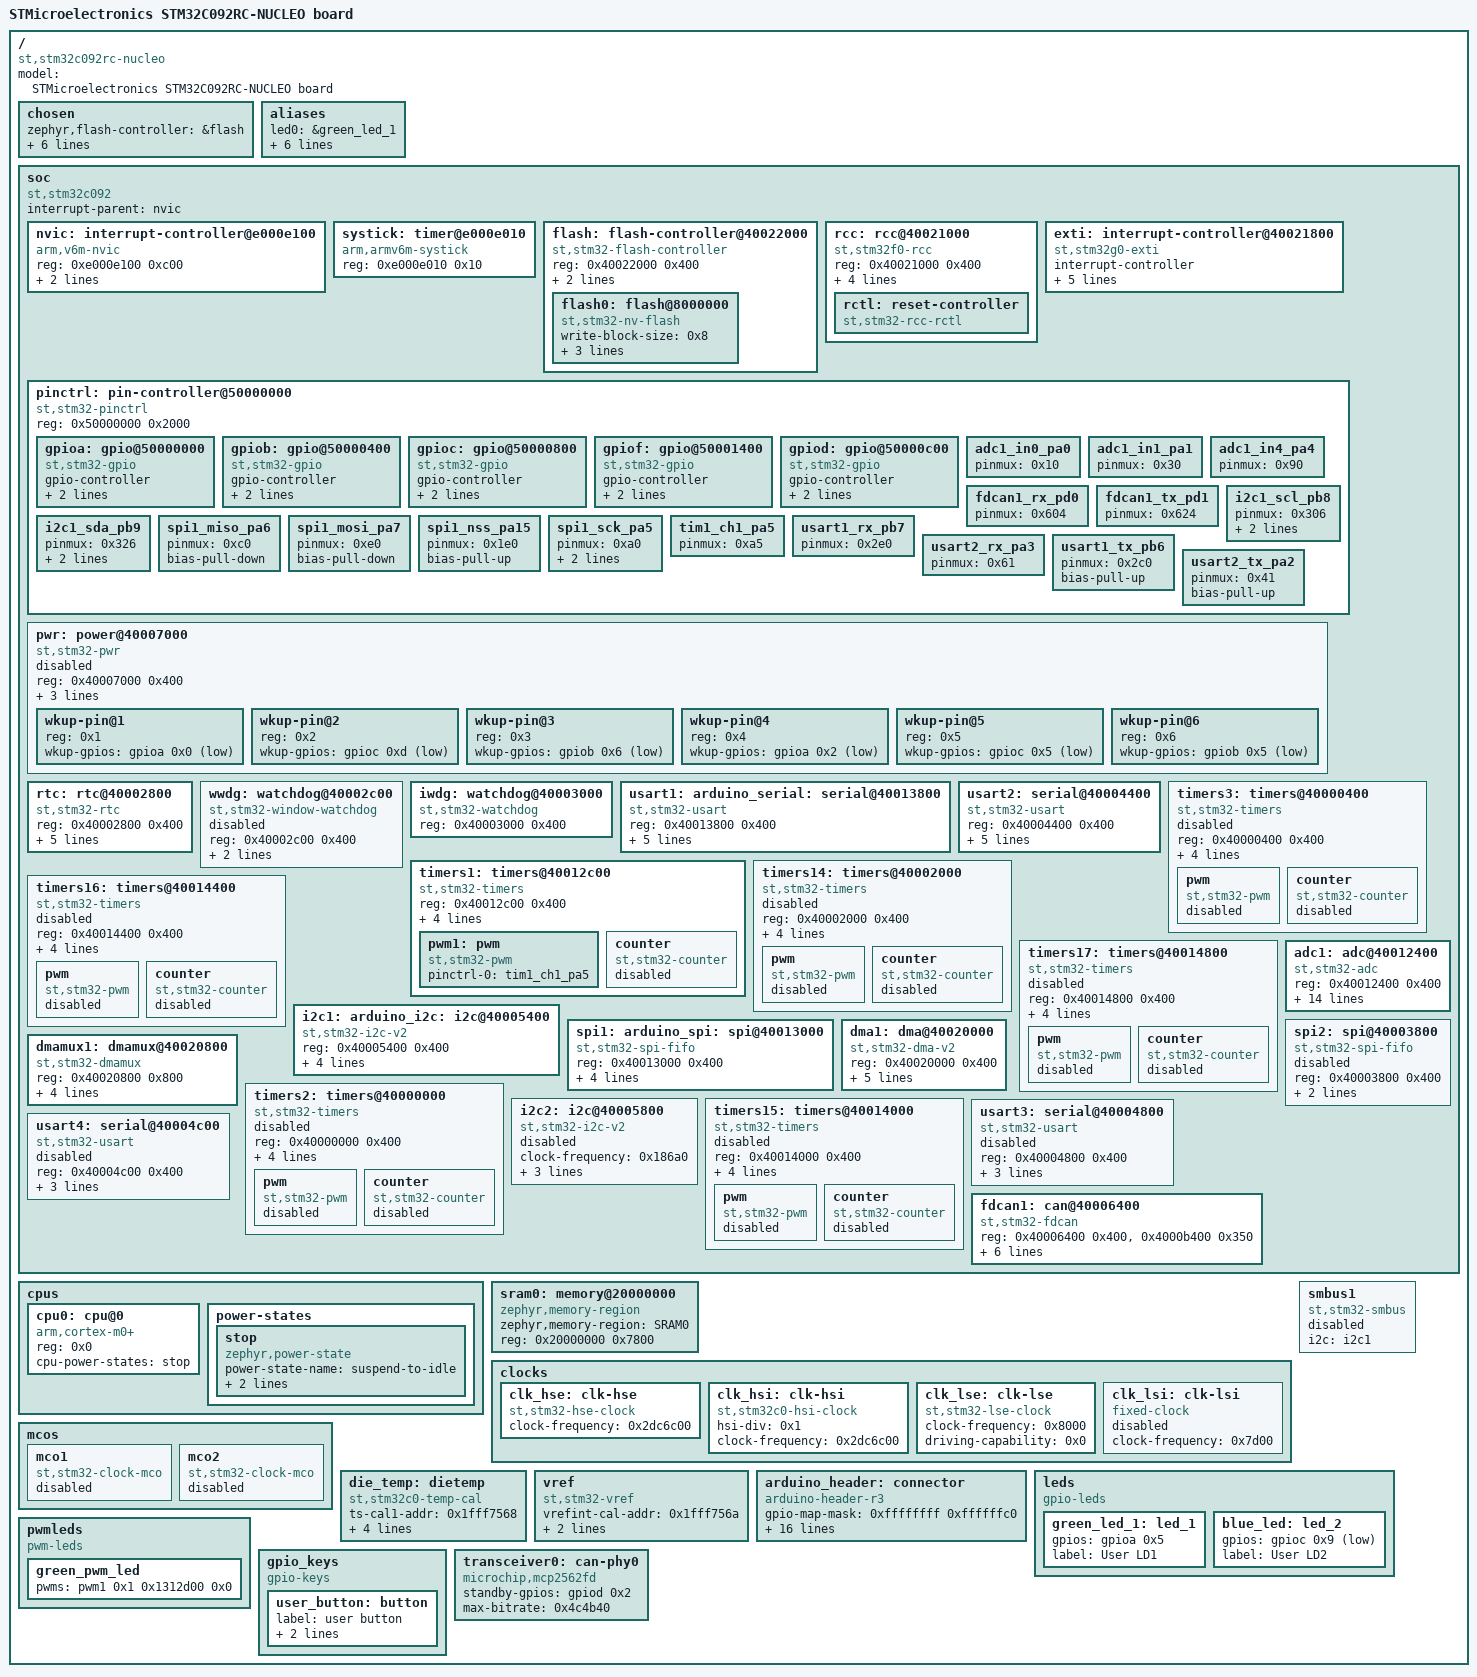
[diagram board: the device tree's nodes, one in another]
/dts-v1/;

/* node '/' defined in zephyr/dts/common/skeleton.dtsi:9 */
/ {
	#address-cells = < 0x1 >;                              /* in zephyr/dts/common/skeleton.dtsi:10 */
	#size-cells = < 0x1 >;                                 /* in zephyr/dts/common/skeleton.dtsi:11 */
	model = "STMicroelectronics STM32C092RC-NUCLEO board"; /* in zephyr/boards/st/nucleo_c092rc/nucleo_c092rc.dts:15 */
	compatible = "st,stm32c092rc-nucleo";                  /* in zephyr/boards/st/nucleo_c092rc/nucleo_c092rc.dts:16 */

	/* node '/chosen' defined in zephyr/dts/common/skeleton.dtsi:13 */
	chosen {
		zephyr,flash-controller = &flash;  /* in zephyr/dts/arm/st/c0/stm32c0.dtsi:75 */
		zephyr,cortex-m-idle-timer = &rtc; /* in zephyr/dts/arm/st/c0/stm32c0.dtsi:76 */
		zephyr,console = &usart2;          /* in zephyr/boards/st/nucleo_c092rc/nucleo_c092rc.dts:19 */
		zephyr,shell-uart = &usart2;       /* in zephyr/boards/st/nucleo_c092rc/nucleo_c092rc.dts:20 */
		zephyr,sram = &sram0;              /* in zephyr/boards/st/nucleo_c092rc/nucleo_c092rc.dts:21 */
		zephyr,flash = &flash0;            /* in zephyr/boards/st/nucleo_c092rc/nucleo_c092rc.dts:22 */
		zephyr,canbus = &fdcan1;           /* in zephyr/boards/st/nucleo_c092rc/nucleo_c092rc.dts:23 */
	};

	/* node '/aliases' defined in zephyr/dts/common/skeleton.dtsi:15 */
	aliases {
		led0 = &green_led_1;       /* in zephyr/boards/st/nucleo_c092rc/nucleo_c092rc.dts:67 */
		led1 = &blue_led;          /* in zephyr/boards/st/nucleo_c092rc/nucleo_c092rc.dts:68 */
		pwm-led0 = &green_pwm_led; /* in zephyr/boards/st/nucleo_c092rc/nucleo_c092rc.dts:69 */
		sw0 = &user_button;        /* in zephyr/boards/st/nucleo_c092rc/nucleo_c092rc.dts:70 */
		watchdog0 = &iwdg;         /* in zephyr/boards/st/nucleo_c092rc/nucleo_c092rc.dts:71 */
		die-temp0 = &die_temp;     /* in zephyr/boards/st/nucleo_c092rc/nucleo_c092rc.dts:72 */
		volt-sensor0 = &vref;      /* in zephyr/boards/st/nucleo_c092rc/nucleo_c092rc.dts:73 */
	};

	/* node '/soc' defined in zephyr/dts/arm/armv6-m.dtsi:6 */
	soc {
		#address-cells = < 0x1 >;     /* in zephyr/dts/arm/armv6-m.dtsi:7 */
		#size-cells = < 0x1 >;        /* in zephyr/dts/arm/armv6-m.dtsi:8 */
		interrupt-parent = < &nvic >; /* in zephyr/dts/arm/armv6-m.dtsi:10 */
		ranges;                       /* in zephyr/dts/arm/armv6-m.dtsi:11 */
		compatible = "st,stm32c092",
		             "st,stm32c0",
		             "simple-bus";    /* in zephyr/dts/arm/st/c0/stm32c092.dtsi:11 */

		/* node '/soc/interrupt-controller@e000e100' defined in zephyr/dts/arm/armv6-m.dtsi:13 */
		nvic: interrupt-controller@e000e100 {
			#address-cells = < 0x1 >;            /* in zephyr/dts/arm/armv6-m.dtsi:14 */
			compatible = "arm,v6m-nvic";         /* in zephyr/dts/arm/armv6-m.dtsi:15 */
			reg = < 0xe000e100 0xc00 >;          /* in zephyr/dts/arm/armv6-m.dtsi:16 */
			interrupt-controller;                /* in zephyr/dts/arm/armv6-m.dtsi:17 */
			#interrupt-cells = < 0x2 >;          /* in zephyr/dts/arm/armv6-m.dtsi:18 */
			arm,num-irq-priority-bits = < 0x2 >; /* in zephyr/dts/arm/st/c0/stm32c0.dtsi:526 */
			phandle = < 0x1 >;                   /* in zephyr/dts/arm/armv6-m.dtsi:10 */
		};

		/* node '/soc/timer@e000e010' defined in zephyr/dts/arm/armv6-m.dtsi:21 */
		systick: timer@e000e010 {
			compatible = "arm,armv6m-systick"; /* in zephyr/dts/arm/armv6-m.dtsi:22 */
			reg = < 0xe000e010 0x10 >;         /* in zephyr/dts/arm/armv6-m.dtsi:23 */
		};

		/* node '/soc/flash-controller@40022000' defined in zephyr/dts/arm/st/c0/stm32c0.dtsi:155 */
		flash: flash-controller@40022000 {
			compatible = "st,stm32-flash-controller",
			             "st,stm32g0-flash-controller"; /* in zephyr/dts/arm/st/c0/stm32c0.dtsi:156 */
			reg = < 0x40022000 0x400 >;                 /* in zephyr/dts/arm/st/c0/stm32c0.dtsi:157 */
			interrupts = < 0x3 0x0 >;                   /* in zephyr/dts/arm/st/c0/stm32c0.dtsi:158 */
			clocks = < &rcc 0x38 0x100 >;               /* in zephyr/dts/arm/st/c0/stm32c0.dtsi:159 */
			#address-cells = < 0x1 >;                   /* in zephyr/dts/arm/st/c0/stm32c0.dtsi:161 */
			#size-cells = < 0x1 >;                      /* in zephyr/dts/arm/st/c0/stm32c0.dtsi:162 */

			/* node '/soc/flash-controller@40022000/flash@8000000' defined in zephyr/dts/arm/st/c0/stm32c0.dtsi:164 */
			flash0: flash@8000000 {
				compatible = "st,stm32-nv-flash",
				             "soc-nv-flash";      /* in zephyr/dts/arm/st/c0/stm32c0.dtsi:165 */
				write-block-size = < 0x8 >;       /* in zephyr/dts/arm/st/c0/stm32c0.dtsi:167 */
				erase-block-size = < 0x800 >;     /* in zephyr/dts/arm/st/c0/stm32c0.dtsi:168 */
				max-erase-time = < 0x28 >;        /* in zephyr/dts/arm/st/c0/stm32c0.dtsi:170 */
				reg = < 0x8000000 0x40000 >;      /* in zephyr/dts/arm/st/c0/stm32c092Xc.dtsi:19 */
			};
		};

		/* node '/soc/rcc@40021000' defined in zephyr/dts/arm/st/c0/stm32c0.dtsi:174 */
		rcc: rcc@40021000 {
			compatible = "st,stm32f0-rcc";   /* in zephyr/dts/arm/st/c0/stm32c0.dtsi:175 */
			#clock-cells = < 0x2 >;          /* in zephyr/dts/arm/st/c0/stm32c0.dtsi:176 */
			reg = < 0x40021000 0x400 >;      /* in zephyr/dts/arm/st/c0/stm32c0.dtsi:177 */
			clocks = < &clk_hse >;           /* in zephyr/boards/st/nucleo_c092rc/nucleo_c092rc.dts:108 */
			clock-frequency = < 0x2dc6c00 >; /* in zephyr/boards/st/nucleo_c092rc/nucleo_c092rc.dts:109 */
			ahb-prescaler = < 0x1 >;         /* in zephyr/boards/st/nucleo_c092rc/nucleo_c092rc.dts:110 */
			apb1-prescaler = < 0x1 >;        /* in zephyr/boards/st/nucleo_c092rc/nucleo_c092rc.dts:111 */
			phandle = < 0x2 >;               /* in zephyr/dts/arm/st/c0/stm32c0.dtsi:159 */

			/* node '/soc/rcc@40021000/reset-controller' defined in zephyr/dts/arm/st/c0/stm32c0.dtsi:179 */
			rctl: reset-controller {
				compatible = "st,stm32-rcc-rctl"; /* in zephyr/dts/arm/st/c0/stm32c0.dtsi:180 */
				#reset-cells = < 0x1 >;           /* in zephyr/dts/arm/st/c0/stm32c0.dtsi:181 */
				phandle = < 0x7 >;                /* in zephyr/dts/arm/st/c0/stm32c0.dtsi:306 */
			};
		};

		/* node '/soc/interrupt-controller@40021800' defined in zephyr/dts/arm/st/c0/stm32c0.dtsi:185 */
		exti: interrupt-controller@40021800 {
			compatible = "st,stm32g0-exti",
			             "st,stm32-exti";   /* in zephyr/dts/arm/st/c0/stm32c0.dtsi:186 */
			interrupt-controller;           /* in zephyr/dts/arm/st/c0/stm32c0.dtsi:187 */
			#interrupt-cells = < 0x1 >;     /* in zephyr/dts/arm/st/c0/stm32c0.dtsi:188 */
			#address-cells = < 0x1 >;       /* in zephyr/dts/arm/st/c0/stm32c0.dtsi:189 */
			reg = < 0x40021800 0x400 >;     /* in zephyr/dts/arm/st/c0/stm32c0.dtsi:190 */
			clocks = < &rcc 0x40 0x1 >;     /* in zephyr/dts/arm/st/c0/stm32c0.dtsi:191 */
			num-lines = < 0x20 >;           /* in zephyr/dts/arm/st/c0/stm32c0.dtsi:192 */
			interrupts = < 0x5 0x0 >,
			             < 0x6 0x0 >,
			             < 0x7 0x0 >;       /* in zephyr/dts/arm/st/c0/stm32c0.dtsi:193 */
			interrupt-names = "line0-1",
			                  "line2-3",
			                  "line4-15";   /* in zephyr/dts/arm/st/c0/stm32c0.dtsi:194 */
			line-ranges = < 0x0 0x2 >,
			              < 0x2 0x2 >,
			              < 0x4 0xc >;      /* in zephyr/dts/arm/st/c0/stm32c0.dtsi:195 */
		};

		/* node '/soc/pin-controller@50000000' defined in zephyr/dts/arm/st/c0/stm32c0.dtsi:198 */
		pinctrl: pin-controller@50000000 {
			compatible = "st,stm32-pinctrl"; /* in zephyr/dts/arm/st/c0/stm32c0.dtsi:199 */
			#address-cells = < 0x1 >;        /* in zephyr/dts/arm/st/c0/stm32c0.dtsi:200 */
			#size-cells = < 0x1 >;           /* in zephyr/dts/arm/st/c0/stm32c0.dtsi:201 */
			reg = < 0x50000000 0x2000 >;     /* in zephyr/dts/arm/st/c0/stm32c0.dtsi:202 */

			/* node '/soc/pin-controller@50000000/gpio@50000000' defined in zephyr/dts/arm/st/c0/stm32c0.dtsi:204 */
			gpioa: gpio@50000000 {
				compatible = "st,stm32-gpio"; /* in zephyr/dts/arm/st/c0/stm32c0.dtsi:205 */
				gpio-controller;              /* in zephyr/dts/arm/st/c0/stm32c0.dtsi:206 */
				#gpio-cells = < 0x2 >;        /* in zephyr/dts/arm/st/c0/stm32c0.dtsi:207 */
				reg = < 0x50000000 0x400 >;   /* in zephyr/dts/arm/st/c0/stm32c0.dtsi:208 */
				clocks = < &rcc 0x34 0x1 >;   /* in zephyr/dts/arm/st/c0/stm32c0.dtsi:209 */
				phandle = < 0x4 >;            /* in zephyr/dts/arm/st/c0/stm32c0.dtsi:251 */
			};

			/* node '/soc/pin-controller@50000000/gpio@50000400' defined in zephyr/dts/arm/st/c0/stm32c0.dtsi:212 */
			gpiob: gpio@50000400 {
				compatible = "st,stm32-gpio"; /* in zephyr/dts/arm/st/c0/stm32c0.dtsi:213 */
				gpio-controller;              /* in zephyr/dts/arm/st/c0/stm32c0.dtsi:214 */
				#gpio-cells = < 0x2 >;        /* in zephyr/dts/arm/st/c0/stm32c0.dtsi:215 */
				reg = < 0x50000400 0x400 >;   /* in zephyr/dts/arm/st/c0/stm32c0.dtsi:216 */
				clocks = < &rcc 0x34 0x2 >;   /* in zephyr/dts/arm/st/c0/stm32c0.dtsi:217 */
				phandle = < 0x6 >;            /* in zephyr/dts/arm/st/c0/stm32c0.dtsi:260 */
			};

			/* node '/soc/pin-controller@50000000/gpio@50000800' defined in zephyr/dts/arm/st/c0/stm32c0.dtsi:220 */
			gpioc: gpio@50000800 {
				compatible = "st,stm32-gpio"; /* in zephyr/dts/arm/st/c0/stm32c0.dtsi:221 */
				gpio-controller;              /* in zephyr/dts/arm/st/c0/stm32c0.dtsi:222 */
				#gpio-cells = < 0x2 >;        /* in zephyr/dts/arm/st/c0/stm32c0.dtsi:223 */
				reg = < 0x50000800 0x400 >;   /* in zephyr/dts/arm/st/c0/stm32c0.dtsi:224 */
				clocks = < &rcc 0x34 0x4 >;   /* in zephyr/dts/arm/st/c0/stm32c0.dtsi:225 */
				phandle = < 0x5 >;            /* in zephyr/boards/st/nucleo_c092rc/nucleo_c092rc.dts:80 */
			};

			/* node '/soc/pin-controller@50000000/gpio@50001400' defined in zephyr/dts/arm/st/c0/stm32c0.dtsi:228 */
			gpiof: gpio@50001400 {
				compatible = "st,stm32-gpio"; /* in zephyr/dts/arm/st/c0/stm32c0.dtsi:229 */
				gpio-controller;              /* in zephyr/dts/arm/st/c0/stm32c0.dtsi:230 */
				#gpio-cells = < 0x2 >;        /* in zephyr/dts/arm/st/c0/stm32c0.dtsi:231 */
				reg = < 0x50001400 0x400 >;   /* in zephyr/dts/arm/st/c0/stm32c0.dtsi:232 */
				clocks = < &rcc 0x34 0x20 >;  /* in zephyr/dts/arm/st/c0/stm32c0.dtsi:233 */
			};

			/* node '/soc/pin-controller@50000000/gpio@50000c00' defined in zephyr/dts/arm/st/c0/stm32c031.dtsi:14 */
			gpiod: gpio@50000c00 {
				compatible = "st,stm32-gpio"; /* in zephyr/dts/arm/st/c0/stm32c031.dtsi:15 */
				gpio-controller;              /* in zephyr/dts/arm/st/c0/stm32c031.dtsi:16 */
				#gpio-cells = < 0x2 >;        /* in zephyr/dts/arm/st/c0/stm32c031.dtsi:17 */
				reg = < 0x50000c00 0x400 >;   /* in zephyr/dts/arm/st/c0/stm32c031.dtsi:18 */
				clocks = < &rcc 0x34 0x8 >;   /* in zephyr/dts/arm/st/c0/stm32c031.dtsi:19 */
				phandle = < 0x1d >;           /* in zephyr/boards/st/nucleo_c092rc/nucleo_c092rc.dts:61 */
			};

			/* node '/soc/pin-controller@50000000/adc1_in0_pa0' defined in modules/hal/stm32/dts/st/c0/stm32c092rctx-pinctrl.dtsi:15 */
			adc1_in0_pa0: adc1_in0_pa0 {
				pinmux = < 0x10 >;  /* in modules/hal/stm32/dts/st/c0/stm32c092rctx-pinctrl.dtsi:16 */
				phandle = < 0x13 >; /* in zephyr/boards/st/nucleo_c092rc/nucleo_c092rc.dts:165 */
			};

			/* node '/soc/pin-controller@50000000/adc1_in1_pa1' defined in modules/hal/stm32/dts/st/c0/stm32c092rctx-pinctrl.dtsi:19 */
			adc1_in1_pa1: adc1_in1_pa1 {
				pinmux = < 0x30 >;  /* in modules/hal/stm32/dts/st/c0/stm32c092rctx-pinctrl.dtsi:20 */
				phandle = < 0x14 >; /* in zephyr/boards/st/nucleo_c092rc/nucleo_c092rc.dts:165 */
			};

			/* node '/soc/pin-controller@50000000/adc1_in4_pa4' defined in modules/hal/stm32/dts/st/c0/stm32c092rctx-pinctrl.dtsi:31 */
			adc1_in4_pa4: adc1_in4_pa4 {
				pinmux = < 0x90 >;  /* in modules/hal/stm32/dts/st/c0/stm32c092rctx-pinctrl.dtsi:32 */
				phandle = < 0x15 >; /* in zephyr/boards/st/nucleo_c092rc/nucleo_c092rc.dts:165 */
			};

			/* node '/soc/pin-controller@50000000/fdcan1_rx_pd0' defined in modules/hal/stm32/dts/st/c0/stm32c092rctx-pinctrl.dtsi:367 */
			fdcan1_rx_pd0: fdcan1_rx_pd0 {
				pinmux = < 0x604 >; /* in modules/hal/stm32/dts/st/c0/stm32c092rctx-pinctrl.dtsi:368 */
				phandle = < 0x16 >; /* in zephyr/boards/st/nucleo_c092rc/nucleo_c092rc.dts:197 */
			};

			/* node '/soc/pin-controller@50000000/fdcan1_tx_pd1' defined in modules/hal/stm32/dts/st/c0/stm32c092rctx-pinctrl.dtsi:405 */
			fdcan1_tx_pd1: fdcan1_tx_pd1 {
				pinmux = < 0x624 >; /* in modules/hal/stm32/dts/st/c0/stm32c092rctx-pinctrl.dtsi:406 */
				phandle = < 0x17 >; /* in zephyr/boards/st/nucleo_c092rc/nucleo_c092rc.dts:197 */
			};

			/* node '/soc/pin-controller@50000000/i2c1_scl_pb8' defined in modules/hal/stm32/dts/st/c0/stm32c092rctx-pinctrl.dtsi:429 */
			i2c1_scl_pb8: i2c1_scl_pb8 {
				pinmux = < 0x306 >; /* in modules/hal/stm32/dts/st/c0/stm32c092rctx-pinctrl.dtsi:430 */
				bias-pull-up;       /* in modules/hal/stm32/dts/st/c0/stm32c092rctx-pinctrl.dtsi:431 */
				drive-open-drain;   /* in modules/hal/stm32/dts/st/c0/stm32c092rctx-pinctrl.dtsi:432 */
				phandle = < 0xd >;  /* in zephyr/boards/st/nucleo_c092rc/nucleo_c092rc.dts:150 */
			};

			/* node '/soc/pin-controller@50000000/i2c1_sda_pb9' defined in modules/hal/stm32/dts/st/c0/stm32c092rctx-pinctrl.dtsi:485 */
			i2c1_sda_pb9: i2c1_sda_pb9 {
				pinmux = < 0x326 >; /* in modules/hal/stm32/dts/st/c0/stm32c092rctx-pinctrl.dtsi:486 */
				bias-pull-up;       /* in modules/hal/stm32/dts/st/c0/stm32c092rctx-pinctrl.dtsi:487 */
				drive-open-drain;   /* in modules/hal/stm32/dts/st/c0/stm32c092rctx-pinctrl.dtsi:488 */
				phandle = < 0xe >;  /* in zephyr/boards/st/nucleo_c092rc/nucleo_c092rc.dts:150 */
			};

			/* node '/soc/pin-controller@50000000/spi1_miso_pa6' defined in modules/hal/stm32/dts/st/c0/stm32c092rctx-pinctrl.dtsi:710 */
			spi1_miso_pa6: spi1_miso_pa6 {
				pinmux = < 0xc0 >;  /* in modules/hal/stm32/dts/st/c0/stm32c092rctx-pinctrl.dtsi:711 */
				bias-pull-down;     /* in modules/hal/stm32/dts/st/c0/stm32c092rctx-pinctrl.dtsi:712 */
				phandle = < 0x11 >; /* in zephyr/boards/st/nucleo_c092rc/nucleo_c092rc.dts:158 */
			};

			/* node '/soc/pin-controller@50000000/spi1_mosi_pa7' defined in modules/hal/stm32/dts/st/c0/stm32c092rctx-pinctrl.dtsi:782 */
			spi1_mosi_pa7: spi1_mosi_pa7 {
				pinmux = < 0xe0 >;  /* in modules/hal/stm32/dts/st/c0/stm32c092rctx-pinctrl.dtsi:783 */
				bias-pull-down;     /* in modules/hal/stm32/dts/st/c0/stm32c092rctx-pinctrl.dtsi:784 */
				phandle = < 0x12 >; /* in zephyr/boards/st/nucleo_c092rc/nucleo_c092rc.dts:158 */
			};

			/* node '/soc/pin-controller@50000000/spi1_nss_pa15' defined in modules/hal/stm32/dts/st/c0/stm32c092rctx-pinctrl.dtsi:859 */
			spi1_nss_pa15: spi1_nss_pa15 {
				pinmux = < 0x1e0 >; /* in modules/hal/stm32/dts/st/c0/stm32c092rctx-pinctrl.dtsi:860 */
				bias-pull-up;       /* in modules/hal/stm32/dts/st/c0/stm32c092rctx-pinctrl.dtsi:861 */
				phandle = < 0xf >;  /* in zephyr/boards/st/nucleo_c092rc/nucleo_c092rc.dts:158 */
			};

			/* node '/soc/pin-controller@50000000/spi1_sck_pa5' defined in modules/hal/stm32/dts/st/c0/stm32c092rctx-pinctrl.dtsi:907 */
			spi1_sck_pa5: spi1_sck_pa5 {
				pinmux = < 0xa0 >;             /* in modules/hal/stm32/dts/st/c0/stm32c092rctx-pinctrl.dtsi:908 */
				bias-pull-down;                /* in modules/hal/stm32/dts/st/c0/stm32c092rctx-pinctrl.dtsi:909 */
				slew-rate = "very-high-speed"; /* in modules/hal/stm32/dts/st/c0/stm32c092rctx-pinctrl.dtsi:910 */
				phandle = < 0x10 >;            /* in zephyr/boards/st/nucleo_c092rc/nucleo_c092rc.dts:158 */
			};

			/* node '/soc/pin-controller@50000000/tim1_ch1_pa5' defined in modules/hal/stm32/dts/st/c0/stm32c092rctx-pinctrl.dtsi:1053 */
			tim1_ch1_pa5: tim1_ch1_pa5 {
				pinmux = < 0xa5 >; /* in modules/hal/stm32/dts/st/c0/stm32c092rctx-pinctrl.dtsi:1054 */
				phandle = < 0xc >; /* in zephyr/boards/st/nucleo_c092rc/nucleo_c092rc.dts:143 */
			};

			/* node '/soc/pin-controller@50000000/usart1_rx_pb7' defined in modules/hal/stm32/dts/st/c0/stm32c092rctx-pinctrl.dtsi:1637 */
			usart1_rx_pb7: usart1_rx_pb7 {
				pinmux = < 0x2e0 >; /* in modules/hal/stm32/dts/st/c0/stm32c092rctx-pinctrl.dtsi:1638 */
				phandle = < 0x9 >;  /* in zephyr/boards/st/nucleo_c092rc/nucleo_c092rc.dts:115 */
			};

			/* node '/soc/pin-controller@50000000/usart2_rx_pa3' defined in modules/hal/stm32/dts/st/c0/stm32c092rctx-pinctrl.dtsi:1645 */
			usart2_rx_pa3: usart2_rx_pa3 {
				pinmux = < 0x61 >; /* in modules/hal/stm32/dts/st/c0/stm32c092rctx-pinctrl.dtsi:1646 */
				phandle = < 0xb >; /* in zephyr/boards/st/nucleo_c092rc/nucleo_c092rc.dts:122 */
			};

			/* node '/soc/pin-controller@50000000/usart1_tx_pb6' defined in modules/hal/stm32/dts/st/c0/stm32c092rctx-pinctrl.dtsi:1721 */
			usart1_tx_pb6: usart1_tx_pb6 {
				pinmux = < 0x2c0 >; /* in modules/hal/stm32/dts/st/c0/stm32c092rctx-pinctrl.dtsi:1722 */
				bias-pull-up;       /* in modules/hal/stm32/dts/st/c0/stm32c092rctx-pinctrl.dtsi:1723 */
				phandle = < 0x8 >;  /* in zephyr/boards/st/nucleo_c092rc/nucleo_c092rc.dts:115 */
			};

			/* node '/soc/pin-controller@50000000/usart2_tx_pa2' defined in modules/hal/stm32/dts/st/c0/stm32c092rctx-pinctrl.dtsi:1736 */
			usart2_tx_pa2: usart2_tx_pa2 {
				pinmux = < 0x41 >; /* in modules/hal/stm32/dts/st/c0/stm32c092rctx-pinctrl.dtsi:1737 */
				bias-pull-up;      /* in modules/hal/stm32/dts/st/c0/stm32c092rctx-pinctrl.dtsi:1738 */
				phandle = < 0xa >; /* in zephyr/boards/st/nucleo_c092rc/nucleo_c092rc.dts:122 */
			};
		};

		/* node '/soc/power@40007000' defined in zephyr/dts/arm/st/c0/stm32c0.dtsi:237 */
		pwr: power@40007000 {
			compatible = "st,stm32-pwr"; /* in zephyr/dts/arm/st/c0/stm32c0.dtsi:238 */
			reg = < 0x40007000 0x400 >;  /* in zephyr/dts/arm/st/c0/stm32c0.dtsi:239 */
			status = "disabled";         /* in zephyr/dts/arm/st/c0/stm32c0.dtsi:240 */
			wkup-pins-nb = < 0x6 >;      /* in zephyr/dts/arm/st/c0/stm32c0.dtsi:242 */
			wkup-pins-pol;               /* in zephyr/dts/arm/st/c0/stm32c0.dtsi:243 */
			wkup-pins-pupd;              /* in zephyr/dts/arm/st/c0/stm32c0.dtsi:244 */
			#address-cells = < 0x1 >;    /* in zephyr/dts/arm/st/c0/stm32c0.dtsi:246 */
			#size-cells = < 0x0 >;       /* in zephyr/dts/arm/st/c0/stm32c0.dtsi:247 */

			/* node '/soc/power@40007000/wkup-pin@1' defined in zephyr/dts/arm/st/c0/stm32c0.dtsi:249 */
			wkup-pin@1 {
				reg = < 0x1 >;                   /* in zephyr/dts/arm/st/c0/stm32c0.dtsi:250 */
				wkup-gpios = < &gpioa 0x0 0x1 >; /* in zephyr/dts/arm/st/c0/stm32c0.dtsi:251 */
			};

			/* node '/soc/power@40007000/wkup-pin@2' defined in zephyr/dts/arm/st/c0/stm32c0.dtsi:254 */
			wkup-pin@2 {
				reg = < 0x2 >;                   /* in zephyr/boards/st/nucleo_c092rc/nucleo_c092rc.dts:79 */
				wkup-gpios = < &gpioc 0xd 0x1 >; /* in zephyr/boards/st/nucleo_c092rc/nucleo_c092rc.dts:80 */
			};

			/* node '/soc/power@40007000/wkup-pin@3' defined in zephyr/dts/arm/st/c0/stm32c0.dtsi:258 */
			wkup-pin@3 {
				reg = < 0x3 >;                   /* in zephyr/dts/arm/st/c0/stm32c0.dtsi:259 */
				wkup-gpios = < &gpiob 0x6 0x1 >; /* in zephyr/dts/arm/st/c0/stm32c0.dtsi:260 */
			};

			/* node '/soc/power@40007000/wkup-pin@4' defined in zephyr/dts/arm/st/c0/stm32c0.dtsi:263 */
			wkup-pin@4 {
				reg = < 0x4 >;                   /* in zephyr/dts/arm/st/c0/stm32c0.dtsi:264 */
				wkup-gpios = < &gpioa 0x2 0x1 >; /* in zephyr/dts/arm/st/c0/stm32c0.dtsi:265 */
			};

			/* node '/soc/power@40007000/wkup-pin@5' defined in zephyr/dts/arm/st/c0/stm32c0.dtsi:268 */
			wkup-pin@5 {
				reg = < 0x5 >;                   /* in zephyr/boards/st/nucleo_c092rc/nucleo_c092rc.dts:84 */
				wkup-gpios = < &gpioc 0x5 0x1 >; /* in zephyr/boards/st/nucleo_c092rc/nucleo_c092rc.dts:85 */
			};

			/* node '/soc/power@40007000/wkup-pin@6' defined in zephyr/dts/arm/st/c0/stm32c0.dtsi:272 */
			wkup-pin@6 {
				reg = < 0x6 >;                   /* in zephyr/boards/st/nucleo_c092rc/nucleo_c092rc.dts:89 */
				wkup-gpios = < &gpiob 0x5 0x1 >; /* in zephyr/boards/st/nucleo_c092rc/nucleo_c092rc.dts:90 */
			};
		};

		/* node '/soc/rtc@40002800' defined in zephyr/dts/arm/st/c0/stm32c0.dtsi:277 */
		rtc: rtc@40002800 {
			compatible = "st,stm32-rtc";     /* in zephyr/dts/arm/st/c0/stm32c0.dtsi:278 */
			reg = < 0x40002800 0x400 >;      /* in zephyr/dts/arm/st/c0/stm32c0.dtsi:279 */
			interrupts = < 0x2 0x0 >;        /* in zephyr/dts/arm/st/c0/stm32c0.dtsi:280 */
			prescaler = < 0x8000 >;          /* in zephyr/dts/arm/st/c0/stm32c0.dtsi:282 */
			alarms-count = < 0x1 >;          /* in zephyr/dts/arm/st/c0/stm32c0.dtsi:283 */
			alrm-exti-line = < 0x13 >;       /* in zephyr/dts/arm/st/c0/stm32c0.dtsi:284 */
			clocks = < &rcc 0x3c 0x400 >,
			         < &rcc 0x2 0x8c8005c >; /* in zephyr/boards/st/nucleo_c092rc/nucleo_c092rc.dts:129 */
			status = "okay";                 /* in zephyr/boards/st/nucleo_c092rc/nucleo_c092rc.dts:131 */
		};

		/* node '/soc/watchdog@40002c00' defined in zephyr/dts/arm/st/c0/stm32c0.dtsi:288 */
		wwdg: watchdog@40002c00 {
			compatible = "st,stm32-window-watchdog"; /* in zephyr/dts/arm/st/c0/stm32c0.dtsi:289 */
			reg = < 0x40002c00 0x400 >;              /* in zephyr/dts/arm/st/c0/stm32c0.dtsi:290 */
			clocks = < &rcc 0x3c 0x800 >;            /* in zephyr/dts/arm/st/c0/stm32c0.dtsi:291 */
			interrupts = < 0x0 0x2 >;                /* in zephyr/dts/arm/st/c0/stm32c0.dtsi:292 */
			status = "disabled";                     /* in zephyr/dts/arm/st/c0/stm32c0.dtsi:293 */
		};

		/* node '/soc/watchdog@40003000' defined in zephyr/dts/arm/st/c0/stm32c0.dtsi:296 */
		iwdg: watchdog@40003000 {
			compatible = "st,stm32-watchdog"; /* in zephyr/dts/arm/st/c0/stm32c0.dtsi:297 */
			reg = < 0x40003000 0x400 >;       /* in zephyr/dts/arm/st/c0/stm32c0.dtsi:298 */
			status = "okay";                  /* in zephyr/boards/st/nucleo_c092rc/nucleo_c092rc.dts:135 */
		};

		/* node '/soc/serial@40013800' defined in zephyr/dts/arm/st/c0/stm32c0.dtsi:302 */
		usart1: arduino_serial: serial@40013800 {
			compatible = "st,stm32-usart",
			             "st,stm32-uart";                  /* in zephyr/dts/arm/st/c0/stm32c0.dtsi:303 */
			reg = < 0x40013800 0x400 >;                    /* in zephyr/dts/arm/st/c0/stm32c0.dtsi:304 */
			clocks = < &rcc 0x40 0x4000 >;                 /* in zephyr/dts/arm/st/c0/stm32c0.dtsi:305 */
			resets = < &rctl 0x60e >;                      /* in zephyr/dts/arm/st/c0/stm32c0.dtsi:306 */
			interrupts = < 0x1b 0x0 >;                     /* in zephyr/dts/arm/st/c0/stm32c0.dtsi:307 */
			pinctrl-0 = < &usart1_tx_pb6 &usart1_rx_pb7 >; /* in zephyr/boards/st/nucleo_c092rc/nucleo_c092rc.dts:115 */
			pinctrl-names = "default";                     /* in zephyr/boards/st/nucleo_c092rc/nucleo_c092rc.dts:116 */
			current-speed = < 0x1c200 >;                   /* in zephyr/boards/st/nucleo_c092rc/nucleo_c092rc.dts:117 */
			status = "okay";                               /* in zephyr/boards/st/nucleo_c092rc/nucleo_c092rc.dts:118 */
		};

		/* node '/soc/serial@40004400' defined in zephyr/dts/arm/st/c0/stm32c0.dtsi:311 */
		usart2: serial@40004400 {
			compatible = "st,stm32-usart",
			             "st,stm32-uart";                  /* in zephyr/dts/arm/st/c0/stm32c0.dtsi:312 */
			reg = < 0x40004400 0x400 >;                    /* in zephyr/dts/arm/st/c0/stm32c0.dtsi:313 */
			clocks = < &rcc 0x3c 0x20000 >;                /* in zephyr/dts/arm/st/c0/stm32c0.dtsi:314 */
			resets = < &rctl 0x591 >;                      /* in zephyr/dts/arm/st/c0/stm32c0.dtsi:315 */
			interrupts = < 0x1c 0x0 >;                     /* in zephyr/dts/arm/st/c0/stm32c0.dtsi:316 */
			pinctrl-0 = < &usart2_tx_pa2 &usart2_rx_pa3 >; /* in zephyr/boards/st/nucleo_c092rc/nucleo_c092rc.dts:122 */
			pinctrl-names = "default";                     /* in zephyr/boards/st/nucleo_c092rc/nucleo_c092rc.dts:123 */
			current-speed = < 0x1c200 >;                   /* in zephyr/boards/st/nucleo_c092rc/nucleo_c092rc.dts:124 */
			status = "okay";                               /* in zephyr/boards/st/nucleo_c092rc/nucleo_c092rc.dts:125 */
		};

		/* node '/soc/timers@40012c00' defined in zephyr/dts/arm/st/c0/stm32c0.dtsi:320 */
		timers1: timers@40012c00 {
			compatible = "st,stm32-timers";     /* in zephyr/dts/arm/st/c0/stm32c0.dtsi:321 */
			reg = < 0x40012c00 0x400 >;         /* in zephyr/dts/arm/st/c0/stm32c0.dtsi:322 */
			clocks = < &rcc 0x40 0x800 >,
			         < &rcc 0x8 0xff >;         /* in zephyr/dts/arm/st/c0/stm32c0.dtsi:323 */
			resets = < &rctl 0x60b >;           /* in zephyr/dts/arm/st/c0/stm32c0.dtsi:325 */
			interrupts = < 0xd 0x0 >,
			             < 0xe 0x0 >;           /* in zephyr/dts/arm/st/c0/stm32c0.dtsi:326 */
			interrupt-names = "brk_up_trg_com",
			                  "cc";             /* in zephyr/dts/arm/st/c0/stm32c0.dtsi:327 */
			st,prescaler = < 0x2710 >;          /* in zephyr/boards/st/nucleo_c092rc/nucleo_c092rc.dts:139 */
			status = "okay";                    /* in zephyr/boards/st/nucleo_c092rc/nucleo_c092rc.dts:140 */

			/* node '/soc/timers@40012c00/pwm' defined in zephyr/dts/arm/st/c0/stm32c0.dtsi:331 */
			pwm1: pwm {
				compatible = "st,stm32-pwm";   /* in zephyr/dts/arm/st/c0/stm32c0.dtsi:332 */
				#pwm-cells = < 0x3 >;          /* in zephyr/dts/arm/st/c0/stm32c0.dtsi:334 */
				pinctrl-0 = < &tim1_ch1_pa5 >; /* in zephyr/boards/st/nucleo_c092rc/nucleo_c092rc.dts:143 */
				pinctrl-names = "default";     /* in zephyr/boards/st/nucleo_c092rc/nucleo_c092rc.dts:144 */
				status = "okay";               /* in zephyr/boards/st/nucleo_c092rc/nucleo_c092rc.dts:145 */
				phandle = < 0x1c >;            /* in zephyr/boards/st/nucleo_c092rc/nucleo_c092rc.dts:44 */
			};

			/* node '/soc/timers@40012c00/counter' defined in zephyr/dts/arm/st/c0/stm32c0.dtsi:337 */
			counter {
				compatible = "st,stm32-counter"; /* in zephyr/dts/arm/st/c0/stm32c0.dtsi:338 */
				status = "disabled";             /* in zephyr/dts/arm/st/c0/stm32c0.dtsi:339 */
			};
		};

		/* node '/soc/timers@40000400' defined in zephyr/dts/arm/st/c0/stm32c0.dtsi:343 */
		timers3: timers@40000400 {
			compatible = "st,stm32-timers"; /* in zephyr/dts/arm/st/c0/stm32c0.dtsi:344 */
			reg = < 0x40000400 0x400 >;     /* in zephyr/dts/arm/st/c0/stm32c0.dtsi:345 */
			clocks = < &rcc 0x3c 0x2 >,
			         < &rcc 0x8 0xff >;     /* in zephyr/dts/arm/st/c0/stm32c0.dtsi:346 */
			resets = < &rctl 0x581 >;       /* in zephyr/dts/arm/st/c0/stm32c0.dtsi:348 */
			interrupts = < 0x10 0x0 >;      /* in zephyr/dts/arm/st/c0/stm32c0.dtsi:349 */
			interrupt-names = "global";     /* in zephyr/dts/arm/st/c0/stm32c0.dtsi:350 */
			st,prescaler = < 0x0 >;         /* in zephyr/dts/arm/st/c0/stm32c0.dtsi:351 */
			status = "disabled";            /* in zephyr/dts/arm/st/c0/stm32c0.dtsi:352 */

			/* node '/soc/timers@40000400/pwm' defined in zephyr/dts/arm/st/c0/stm32c0.dtsi:354 */
			pwm {
				compatible = "st,stm32-pwm"; /* in zephyr/dts/arm/st/c0/stm32c0.dtsi:355 */
				status = "disabled";         /* in zephyr/dts/arm/st/c0/stm32c0.dtsi:356 */
				#pwm-cells = < 0x3 >;        /* in zephyr/dts/arm/st/c0/stm32c0.dtsi:357 */
			};

			/* node '/soc/timers@40000400/counter' defined in zephyr/dts/arm/st/c0/stm32c0.dtsi:360 */
			counter {
				compatible = "st,stm32-counter"; /* in zephyr/dts/arm/st/c0/stm32c0.dtsi:361 */
				status = "disabled";             /* in zephyr/dts/arm/st/c0/stm32c0.dtsi:362 */
			};
		};

		/* node '/soc/timers@40002000' defined in zephyr/dts/arm/st/c0/stm32c0.dtsi:366 */
		timers14: timers@40002000 {
			compatible = "st,stm32-timers"; /* in zephyr/dts/arm/st/c0/stm32c0.dtsi:367 */
			reg = < 0x40002000 0x400 >;     /* in zephyr/dts/arm/st/c0/stm32c0.dtsi:368 */
			clocks = < &rcc 0x40 0x8000 >,
			         < &rcc 0x8 0xff >;     /* in zephyr/dts/arm/st/c0/stm32c0.dtsi:369 */
			resets = < &rctl 0x60f >;       /* in zephyr/dts/arm/st/c0/stm32c0.dtsi:371 */
			interrupts = < 0x13 0x0 >;      /* in zephyr/dts/arm/st/c0/stm32c0.dtsi:372 */
			interrupt-names = "global";     /* in zephyr/dts/arm/st/c0/stm32c0.dtsi:373 */
			st,prescaler = < 0x0 >;         /* in zephyr/dts/arm/st/c0/stm32c0.dtsi:374 */
			status = "disabled";            /* in zephyr/dts/arm/st/c0/stm32c0.dtsi:375 */

			/* node '/soc/timers@40002000/pwm' defined in zephyr/dts/arm/st/c0/stm32c0.dtsi:377 */
			pwm {
				compatible = "st,stm32-pwm"; /* in zephyr/dts/arm/st/c0/stm32c0.dtsi:378 */
				status = "disabled";         /* in zephyr/dts/arm/st/c0/stm32c0.dtsi:379 */
				#pwm-cells = < 0x3 >;        /* in zephyr/dts/arm/st/c0/stm32c0.dtsi:380 */
			};

			/* node '/soc/timers@40002000/counter' defined in zephyr/dts/arm/st/c0/stm32c0.dtsi:383 */
			counter {
				compatible = "st,stm32-counter"; /* in zephyr/dts/arm/st/c0/stm32c0.dtsi:384 */
				status = "disabled";             /* in zephyr/dts/arm/st/c0/stm32c0.dtsi:385 */
			};
		};

		/* node '/soc/timers@40014400' defined in zephyr/dts/arm/st/c0/stm32c0.dtsi:389 */
		timers16: timers@40014400 {
			compatible = "st,stm32-timers"; /* in zephyr/dts/arm/st/c0/stm32c0.dtsi:390 */
			reg = < 0x40014400 0x400 >;     /* in zephyr/dts/arm/st/c0/stm32c0.dtsi:391 */
			clocks = < &rcc 0x40 0x20000 >,
			         < &rcc 0x8 0xff >;     /* in zephyr/dts/arm/st/c0/stm32c0.dtsi:392 */
			resets = < &rctl 0x611 >;       /* in zephyr/dts/arm/st/c0/stm32c0.dtsi:394 */
			interrupts = < 0x15 0x0 >;      /* in zephyr/dts/arm/st/c0/stm32c0.dtsi:395 */
			interrupt-names = "global";     /* in zephyr/dts/arm/st/c0/stm32c0.dtsi:396 */
			st,prescaler = < 0x0 >;         /* in zephyr/dts/arm/st/c0/stm32c0.dtsi:397 */
			status = "disabled";            /* in zephyr/dts/arm/st/c0/stm32c0.dtsi:398 */

			/* node '/soc/timers@40014400/pwm' defined in zephyr/dts/arm/st/c0/stm32c0.dtsi:400 */
			pwm {
				compatible = "st,stm32-pwm"; /* in zephyr/dts/arm/st/c0/stm32c0.dtsi:401 */
				status = "disabled";         /* in zephyr/dts/arm/st/c0/stm32c0.dtsi:402 */
				#pwm-cells = < 0x3 >;        /* in zephyr/dts/arm/st/c0/stm32c0.dtsi:403 */
			};

			/* node '/soc/timers@40014400/counter' defined in zephyr/dts/arm/st/c0/stm32c0.dtsi:406 */
			counter {
				compatible = "st,stm32-counter"; /* in zephyr/dts/arm/st/c0/stm32c0.dtsi:407 */
				status = "disabled";             /* in zephyr/dts/arm/st/c0/stm32c0.dtsi:408 */
			};
		};

		/* node '/soc/timers@40014800' defined in zephyr/dts/arm/st/c0/stm32c0.dtsi:412 */
		timers17: timers@40014800 {
			compatible = "st,stm32-timers"; /* in zephyr/dts/arm/st/c0/stm32c0.dtsi:413 */
			reg = < 0x40014800 0x400 >;     /* in zephyr/dts/arm/st/c0/stm32c0.dtsi:414 */
			clocks = < &rcc 0x40 0x40000 >,
			         < &rcc 0x8 0xff >;     /* in zephyr/dts/arm/st/c0/stm32c0.dtsi:415 */
			resets = < &rctl 0x612 >;       /* in zephyr/dts/arm/st/c0/stm32c0.dtsi:417 */
			interrupts = < 0x16 0x0 >;      /* in zephyr/dts/arm/st/c0/stm32c0.dtsi:418 */
			interrupt-names = "global";     /* in zephyr/dts/arm/st/c0/stm32c0.dtsi:419 */
			st,prescaler = < 0x0 >;         /* in zephyr/dts/arm/st/c0/stm32c0.dtsi:420 */
			status = "disabled";            /* in zephyr/dts/arm/st/c0/stm32c0.dtsi:421 */

			/* node '/soc/timers@40014800/pwm' defined in zephyr/dts/arm/st/c0/stm32c0.dtsi:423 */
			pwm {
				compatible = "st,stm32-pwm"; /* in zephyr/dts/arm/st/c0/stm32c0.dtsi:424 */
				status = "disabled";         /* in zephyr/dts/arm/st/c0/stm32c0.dtsi:425 */
				#pwm-cells = < 0x3 >;        /* in zephyr/dts/arm/st/c0/stm32c0.dtsi:426 */
			};

			/* node '/soc/timers@40014800/counter' defined in zephyr/dts/arm/st/c0/stm32c0.dtsi:429 */
			counter {
				compatible = "st,stm32-counter"; /* in zephyr/dts/arm/st/c0/stm32c0.dtsi:430 */
				status = "disabled";             /* in zephyr/dts/arm/st/c0/stm32c0.dtsi:431 */
			};
		};

		/* node '/soc/i2c@40005400' defined in zephyr/dts/arm/st/c0/stm32c0.dtsi:435 */
		i2c1: arduino_i2c: i2c@40005400 {
			compatible = "st,stm32-i2c-v2";              /* in zephyr/dts/arm/st/c0/stm32c0.dtsi:436 */
			#address-cells = < 0x1 >;                    /* in zephyr/dts/arm/st/c0/stm32c0.dtsi:438 */
			#size-cells = < 0x0 >;                       /* in zephyr/dts/arm/st/c0/stm32c0.dtsi:439 */
			reg = < 0x40005400 0x400 >;                  /* in zephyr/dts/arm/st/c0/stm32c0.dtsi:440 */
			clocks = < &rcc 0x3c 0x200000 >;             /* in zephyr/dts/arm/st/c0/stm32c0.dtsi:441 */
			interrupts = < 0x17 0x0 >;                   /* in zephyr/dts/arm/st/c0/stm32c0.dtsi:442 */
			interrupt-names = "combined";                /* in zephyr/dts/arm/st/c0/stm32c0.dtsi:443 */
			pinctrl-0 = < &i2c1_scl_pb8 &i2c1_sda_pb9 >; /* in zephyr/boards/st/nucleo_c092rc/nucleo_c092rc.dts:150 */
			pinctrl-names = "default";                   /* in zephyr/boards/st/nucleo_c092rc/nucleo_c092rc.dts:151 */
			status = "okay";                             /* in zephyr/boards/st/nucleo_c092rc/nucleo_c092rc.dts:152 */
			clock-frequency = < 0x61a80 >;               /* in zephyr/boards/st/nucleo_c092rc/nucleo_c092rc.dts:153 */
			phandle = < 0x1b >;                          /* in zephyr/dts/arm/st/c0/stm32c0.dtsi:520 */
		};

		/* node '/soc/spi@40013000' defined in zephyr/dts/arm/st/c0/stm32c0.dtsi:447 */
		spi1: arduino_spi: spi@40013000 {
			compatible = "st,stm32-spi-fifo",
			             "st,stm32-spi";                                                /* in zephyr/dts/arm/st/c0/stm32c0.dtsi:448 */
			#address-cells = < 0x1 >;                                                   /* in zephyr/dts/arm/st/c0/stm32c0.dtsi:449 */
			#size-cells = < 0x0 >;                                                      /* in zephyr/dts/arm/st/c0/stm32c0.dtsi:450 */
			reg = < 0x40013000 0x400 >;                                                 /* in zephyr/dts/arm/st/c0/stm32c0.dtsi:451 */
			clocks = < &rcc 0x40 0x1000 >;                                              /* in zephyr/dts/arm/st/c0/stm32c0.dtsi:452 */
			interrupts = < 0x19 0x0 >;                                                  /* in zephyr/dts/arm/st/c0/stm32c0.dtsi:453 */
			pinctrl-0 = < &spi1_nss_pa15 &spi1_sck_pa5 &spi1_miso_pa6 &spi1_mosi_pa7 >; /* in zephyr/boards/st/nucleo_c092rc/nucleo_c092rc.dts:158 */
			pinctrl-names = "default";                                                  /* in zephyr/boards/st/nucleo_c092rc/nucleo_c092rc.dts:160 */
			status = "okay";                                                            /* in zephyr/boards/st/nucleo_c092rc/nucleo_c092rc.dts:161 */
		};

		/* node '/soc/adc@40012400' defined in zephyr/dts/arm/st/c0/stm32c0.dtsi:457 */
		adc1: adc@40012400 {
			compatible = "st,stm32-adc";                               /* in zephyr/dts/arm/st/c0/stm32c0.dtsi:458 */
			reg = < 0x40012400 0x400 >;                                /* in zephyr/dts/arm/st/c0/stm32c0.dtsi:459 */
			interrupts = < 0xc 0x0 >;                                  /* in zephyr/dts/arm/st/c0/stm32c0.dtsi:461 */
			#io-channel-cells = < 0x1 >;                               /* in zephyr/dts/arm/st/c0/stm32c0.dtsi:463 */
			resolutions = < 0x60630c 0x51630c 0x42630c 0x33630c >;     /* in zephyr/dts/arm/st/c0/stm32c0.dtsi:464 */
			sampling-times = < 0x2 0x4 0x8 0xd 0x14 0x28 0x50 0xa1 >;  /* in zephyr/dts/arm/st/c0/stm32c0.dtsi:468 */
			num-sampling-time-common-channels = < 0x2 >;               /* in zephyr/dts/arm/st/c0/stm32c0.dtsi:469 */
			st,adc-sequencer = "NOT_FULLY_CONFIGURABLE";               /* in zephyr/dts/arm/st/c0/stm32c0.dtsi:470 */
			st,adc-oversampler = "OVERSAMPLER_MINIMAL";                /* in zephyr/dts/arm/st/c0/stm32c0.dtsi:471 */
			pinctrl-0 = < &adc1_in0_pa0 &adc1_in1_pa1 &adc1_in4_pa4 >; /* in zephyr/boards/st/nucleo_c092rc/nucleo_c092rc.dts:165 */
			pinctrl-names = "default";                                 /* in zephyr/boards/st/nucleo_c092rc/nucleo_c092rc.dts:166 */
			st,adc-clock-source = "ASYNC";                             /* in zephyr/boards/st/nucleo_c092rc/nucleo_c092rc.dts:167 */
			clocks = < &rcc 0x40 0x100000 >,
			         < &rcc 0x4 0x10de0054 >;                          /* in zephyr/boards/st/nucleo_c092rc/nucleo_c092rc.dts:168 */
			st,adc-prescaler = < 0x4 >;                                /* in zephyr/boards/st/nucleo_c092rc/nucleo_c092rc.dts:170 */
			status = "okay";                                           /* in zephyr/boards/st/nucleo_c092rc/nucleo_c092rc.dts:171 */
			vref-mv = < 0xce4 >;                                       /* in zephyr/boards/st/nucleo_c092rc/nucleo_c092rc.dts:172 */
			phandle = < 0x1a >;                                        /* in zephyr/dts/arm/st/c0/stm32c0.dtsi:504 */
		};

		/* node '/soc/dma@40020000' defined in zephyr/dts/arm/st/c0/stm32c0.dtsi:474 */
		dma1: dma@40020000 {
			compatible = "st,stm32-dma-v2";                                           /* in zephyr/dts/arm/st/c0/stm32c0.dtsi:475 */
			#dma-cells = < 0x3 >;                                                     /* in zephyr/dts/arm/st/c0/stm32c0.dtsi:476 */
			reg = < 0x40020000 0x400 >;                                               /* in zephyr/dts/arm/st/c0/stm32c0.dtsi:477 */
			clocks = < &rcc 0x38 0x1 >;                                               /* in zephyr/dts/arm/st/c0/stm32c0.dtsi:479 */
			dma-offset = < 0x0 >;                                                     /* in zephyr/dts/arm/st/c0/stm32c0.dtsi:481 */
			interrupts = < 0x9 0x0 0xa 0x0 0xa 0x0 0xb 0x0 0xb 0x0 0xb 0x0 0xb 0x0 >; /* in zephyr/dts/arm/st/c0/stm32c091.dtsi:54 */
			dma-requests = < 0x7 >;                                                   /* in zephyr/dts/arm/st/c0/stm32c091.dtsi:55 */
			status = "okay";                                                          /* in zephyr/boards/st/nucleo_c092rc/nucleo_c092rc.dts:184 */
		};

		/* node '/soc/dmamux@40020800' defined in zephyr/dts/arm/st/c0/stm32c0.dtsi:486 */
		dmamux1: dmamux@40020800 {
			compatible = "st,stm32-dmamux"; /* in zephyr/dts/arm/st/c0/stm32c0.dtsi:487 */
			#dma-cells = < 0x3 >;           /* in zephyr/dts/arm/st/c0/stm32c0.dtsi:488 */
			reg = < 0x40020800 0x800 >;     /* in zephyr/dts/arm/st/c0/stm32c0.dtsi:489 */
			interrupts = < 0xb 0x0 >;       /* in zephyr/dts/arm/st/c0/stm32c0.dtsi:490 */
			dma-generators = < 0x4 >;       /* in zephyr/dts/arm/st/c0/stm32c0.dtsi:492 */
			dma-channels = < 0x7 >;         /* in zephyr/dts/arm/st/c0/stm32c091.dtsi:59 */
			dma-requests = < 0x35 >;        /* in zephyr/dts/arm/st/c0/stm32c091.dtsi:60 */
			status = "okay";                /* in zephyr/boards/st/nucleo_c092rc/nucleo_c092rc.dts:188 */
		};

		/* node '/soc/timers@40000000' defined in zephyr/dts/arm/st/c0/stm32c051.dtsi:14 */
		timers2: timers@40000000 {
			compatible = "st,stm32-timers"; /* in zephyr/dts/arm/st/c0/stm32c051.dtsi:15 */
			reg = < 0x40000000 0x400 >;     /* in zephyr/dts/arm/st/c0/stm32c051.dtsi:16 */
			clocks = < &rcc 0x3c 0x1 >,
			         < &rcc 0x8 0xff >;     /* in zephyr/dts/arm/st/c0/stm32c051.dtsi:17 */
			resets = < &rctl 0x580 >;       /* in zephyr/dts/arm/st/c0/stm32c051.dtsi:19 */
			interrupts = < 0xf 0x0 >;       /* in zephyr/dts/arm/st/c0/stm32c051.dtsi:20 */
			interrupt-names = "global";     /* in zephyr/dts/arm/st/c0/stm32c051.dtsi:21 */
			st,prescaler = < 0x0 >;         /* in zephyr/dts/arm/st/c0/stm32c051.dtsi:22 */
			status = "disabled";            /* in zephyr/dts/arm/st/c0/stm32c051.dtsi:23 */

			/* node '/soc/timers@40000000/pwm' defined in zephyr/dts/arm/st/c0/stm32c051.dtsi:25 */
			pwm {
				compatible = "st,stm32-pwm"; /* in zephyr/dts/arm/st/c0/stm32c051.dtsi:26 */
				status = "disabled";         /* in zephyr/dts/arm/st/c0/stm32c051.dtsi:27 */
				#pwm-cells = < 0x3 >;        /* in zephyr/dts/arm/st/c0/stm32c051.dtsi:28 */
			};

			/* node '/soc/timers@40000000/counter' defined in zephyr/dts/arm/st/c0/stm32c051.dtsi:31 */
			counter {
				compatible = "st,stm32-counter"; /* in zephyr/dts/arm/st/c0/stm32c051.dtsi:32 */
				status = "disabled";             /* in zephyr/dts/arm/st/c0/stm32c051.dtsi:33 */
			};
		};

		/* node '/soc/i2c@40005800' defined in zephyr/dts/arm/st/c0/stm32c051.dtsi:37 */
		i2c2: i2c@40005800 {
			compatible = "st,stm32-i2c-v2";  /* in zephyr/dts/arm/st/c0/stm32c051.dtsi:38 */
			clock-frequency = < 0x186a0 >;   /* in zephyr/dts/arm/st/c0/stm32c051.dtsi:39 */
			#address-cells = < 0x1 >;        /* in zephyr/dts/arm/st/c0/stm32c051.dtsi:40 */
			#size-cells = < 0x0 >;           /* in zephyr/dts/arm/st/c0/stm32c051.dtsi:41 */
			reg = < 0x40005800 0x400 >;      /* in zephyr/dts/arm/st/c0/stm32c051.dtsi:42 */
			clocks = < &rcc 0x3c 0x400000 >; /* in zephyr/dts/arm/st/c0/stm32c051.dtsi:43 */
			interrupts = < 0x18 0x0 >;       /* in zephyr/dts/arm/st/c0/stm32c051.dtsi:44 */
			interrupt-names = "global";      /* in zephyr/dts/arm/st/c0/stm32c051.dtsi:45 */
			status = "disabled";             /* in zephyr/dts/arm/st/c0/stm32c051.dtsi:46 */
		};

		/* node '/soc/spi@40003800' defined in zephyr/dts/arm/st/c0/stm32c051.dtsi:49 */
		spi2: spi@40003800 {
			compatible = "st,stm32-spi-fifo",
			             "st,stm32-spi";      /* in zephyr/dts/arm/st/c0/stm32c051.dtsi:50 */
			#address-cells = < 0x1 >;         /* in zephyr/dts/arm/st/c0/stm32c051.dtsi:51 */
			#size-cells = < 0x0 >;            /* in zephyr/dts/arm/st/c0/stm32c051.dtsi:52 */
			reg = < 0x40003800 0x400 >;       /* in zephyr/dts/arm/st/c0/stm32c051.dtsi:53 */
			clocks = < &rcc 0x3c 0x4000 >;    /* in zephyr/dts/arm/st/c0/stm32c051.dtsi:54 */
			interrupts = < 0x1a 0x0 >;        /* in zephyr/dts/arm/st/c0/stm32c051.dtsi:55 */
			interrupt-names = "global";       /* in zephyr/dts/arm/st/c0/stm32c051.dtsi:56 */
			status = "disabled";              /* in zephyr/dts/arm/st/c0/stm32c051.dtsi:57 */
		};

		/* node '/soc/timers@40014000' defined in zephyr/dts/arm/st/c0/stm32c091.dtsi:13 */
		timers15: timers@40014000 {
			compatible = "st,stm32-timers"; /* in zephyr/dts/arm/st/c0/stm32c091.dtsi:14 */
			reg = < 0x40014000 0x400 >;     /* in zephyr/dts/arm/st/c0/stm32c091.dtsi:15 */
			clocks = < &rcc 0x40 0x10000 >; /* in zephyr/dts/arm/st/c0/stm32c091.dtsi:16 */
			resets = < &rctl 0x610 >;       /* in zephyr/dts/arm/st/c0/stm32c091.dtsi:17 */
			interrupts = < 0x14 0x0 >;      /* in zephyr/dts/arm/st/c0/stm32c091.dtsi:18 */
			interrupt-names = "global";     /* in zephyr/dts/arm/st/c0/stm32c091.dtsi:19 */
			st,prescaler = < 0x0 >;         /* in zephyr/dts/arm/st/c0/stm32c091.dtsi:20 */
			status = "disabled";            /* in zephyr/dts/arm/st/c0/stm32c091.dtsi:21 */

			/* node '/soc/timers@40014000/pwm' defined in zephyr/dts/arm/st/c0/stm32c091.dtsi:23 */
			pwm {
				compatible = "st,stm32-pwm"; /* in zephyr/dts/arm/st/c0/stm32c091.dtsi:24 */
				status = "disabled";         /* in zephyr/dts/arm/st/c0/stm32c091.dtsi:25 */
				#pwm-cells = < 0x3 >;        /* in zephyr/dts/arm/st/c0/stm32c091.dtsi:26 */
			};

			/* node '/soc/timers@40014000/counter' defined in zephyr/dts/arm/st/c0/stm32c091.dtsi:29 */
			counter {
				compatible = "st,stm32-counter"; /* in zephyr/dts/arm/st/c0/stm32c091.dtsi:30 */
				status = "disabled";             /* in zephyr/dts/arm/st/c0/stm32c091.dtsi:31 */
			};
		};

		/* node '/soc/serial@40004800' defined in zephyr/dts/arm/st/c0/stm32c091.dtsi:35 */
		usart3: serial@40004800 {
			compatible = "st,stm32-usart",
			             "st,stm32-uart";   /* in zephyr/dts/arm/st/c0/stm32c091.dtsi:36 */
			reg = < 0x40004800 0x400 >;     /* in zephyr/dts/arm/st/c0/stm32c091.dtsi:37 */
			clocks = < &rcc 0x3c 0x40000 >; /* in zephyr/dts/arm/st/c0/stm32c091.dtsi:38 */
			resets = < &rctl 0x592 >;       /* in zephyr/dts/arm/st/c0/stm32c091.dtsi:39 */
			interrupts = < 0x1d 0x0 >;      /* in zephyr/dts/arm/st/c0/stm32c091.dtsi:40 */
			status = "disabled";            /* in zephyr/dts/arm/st/c0/stm32c091.dtsi:41 */
		};

		/* node '/soc/serial@40004c00' defined in zephyr/dts/arm/st/c0/stm32c091.dtsi:44 */
		usart4: serial@40004c00 {
			compatible = "st,stm32-usart",
			             "st,stm32-uart";   /* in zephyr/dts/arm/st/c0/stm32c091.dtsi:45 */
			reg = < 0x40004c00 0x400 >;     /* in zephyr/dts/arm/st/c0/stm32c091.dtsi:46 */
			clocks = < &rcc 0x3c 0x80000 >; /* in zephyr/dts/arm/st/c0/stm32c091.dtsi:47 */
			resets = < &rctl 0x593 >;       /* in zephyr/dts/arm/st/c0/stm32c091.dtsi:48 */
			interrupts = < 0x1d 0x0 >;      /* in zephyr/dts/arm/st/c0/stm32c091.dtsi:49 */
			status = "disabled";            /* in zephyr/dts/arm/st/c0/stm32c091.dtsi:50 */
		};

		/* node '/soc/can@40006400' defined in zephyr/dts/arm/st/c0/stm32c092.dtsi:13 */
		fdcan1: can@40006400 {
			compatible = "st,stm32-fdcan";                         /* in zephyr/dts/arm/st/c0/stm32c092.dtsi:14 */
			reg = < 0x40006400 0x400 >,
			      < 0x4000b400 0x350 >;                            /* in zephyr/dts/arm/st/c0/stm32c092.dtsi:15 */
			reg-names = "m_can",
			            "message_ram";                             /* in zephyr/dts/arm/st/c0/stm32c092.dtsi:16 */
			interrupts = < 0x1e 0x0 >,
			             < 0x1f 0x0 >;                             /* in zephyr/dts/arm/st/c0/stm32c092.dtsi:17 */
			interrupt-names = "int0",
			                  "int1";                              /* in zephyr/dts/arm/st/c0/stm32c092.dtsi:18 */
			bosch,mram-cfg = < 0x0 0x1c 0x8 0x3 0x3 0x0 0x3 0x3 >; /* in zephyr/dts/arm/st/c0/stm32c092.dtsi:20 */
			clocks = < &rcc 0x3c 0x1000 >,
			         < &rcc 0x6 0x10c80054 >;                      /* in zephyr/boards/st/nucleo_c092rc/nucleo_c092rc.dts:195 */
			pinctrl-0 = < &fdcan1_rx_pd0 &fdcan1_tx_pd1 >;         /* in zephyr/boards/st/nucleo_c092rc/nucleo_c092rc.dts:197 */
			pinctrl-names = "default";                             /* in zephyr/boards/st/nucleo_c092rc/nucleo_c092rc.dts:198 */
			phys = < &transceiver0 >;                              /* in zephyr/boards/st/nucleo_c092rc/nucleo_c092rc.dts:199 */
			status = "okay";                                       /* in zephyr/boards/st/nucleo_c092rc/nucleo_c092rc.dts:200 */
		};
	};

	/* node '/cpus' defined in zephyr/dts/arm/st/c0/stm32c0.dtsi:79 */
	cpus {
		#address-cells = < 0x1 >; /* in zephyr/dts/arm/st/c0/stm32c0.dtsi:80 */
		#size-cells = < 0x0 >;    /* in zephyr/dts/arm/st/c0/stm32c0.dtsi:81 */

		/* node '/cpus/cpu@0' defined in zephyr/dts/arm/st/c0/stm32c0.dtsi:83 */
		cpu0: cpu@0 {
			device_type = "cpu";           /* in zephyr/dts/arm/st/c0/stm32c0.dtsi:84 */
			compatible = "arm,cortex-m0+"; /* in zephyr/dts/arm/st/c0/stm32c0.dtsi:85 */
			reg = < 0x0 >;                 /* in zephyr/dts/arm/st/c0/stm32c0.dtsi:86 */
			cpu-power-states = < &stop >;  /* in zephyr/dts/arm/st/c0/stm32c0.dtsi:87 */
		};

		/* node '/cpus/power-states' defined in zephyr/dts/arm/st/c0/stm32c0.dtsi:90 */
		power-states {

			/* node '/cpus/power-states/stop' defined in zephyr/dts/arm/st/c0/stm32c0.dtsi:91 */
			stop: stop {
				compatible = "zephyr,power-state";    /* in zephyr/dts/arm/st/c0/stm32c0.dtsi:92 */
				power-state-name = "suspend-to-idle"; /* in zephyr/dts/arm/st/c0/stm32c0.dtsi:93 */
				min-residency-us = < 0x190 >;         /* in zephyr/dts/arm/st/c0/stm32c0.dtsi:100 */
				exit-latency-us = < 0x12c >;          /* in zephyr/dts/arm/st/c0/stm32c0.dtsi:101 */
				phandle = < 0x19 >;                   /* in zephyr/dts/arm/st/c0/stm32c0.dtsi:87 */
			};
		};
	};

	/* node '/memory@20000000' defined in zephyr/dts/arm/st/c0/stm32c0.dtsi:106 */
	sram0: memory@20000000 {
		compatible = "zephyr,memory-region",
		             "mmio-sram";            /* in zephyr/dts/arm/st/c0/stm32c0.dtsi:107 */
		zephyr,memory-region = "SRAM0";      /* in zephyr/dts/arm/st/c0/stm32c0.dtsi:108 */
		reg = < 0x20000000 0x7800 >;         /* in zephyr/dts/arm/st/c0/stm32c092Xc.dtsi:13 */
	};

	/* node '/clocks' defined in zephyr/dts/arm/st/c0/stm32c0.dtsi:111 */
	clocks {

		/* node '/clocks/clk-hse' defined in zephyr/dts/arm/st/c0/stm32c0.dtsi:112 */
		clk_hse: clk-hse {
			#clock-cells = < 0x0 >;            /* in zephyr/dts/arm/st/c0/stm32c0.dtsi:113 */
			compatible = "st,stm32-hse-clock"; /* in zephyr/dts/arm/st/c0/stm32c0.dtsi:114 */
			clock-frequency = < 0x2dc6c00 >;   /* in zephyr/boards/st/nucleo_c092rc/nucleo_c092rc.dts:99 */
			status = "okay";                   /* in zephyr/boards/st/nucleo_c092rc/nucleo_c092rc.dts:100 */
			phandle = < 0x3 >;                 /* in zephyr/boards/st/nucleo_c092rc/nucleo_c092rc.dts:108 */
		};

		/* node '/clocks/clk-hsi' defined in zephyr/dts/arm/st/c0/stm32c0.dtsi:118 */
		clk_hsi: clk-hsi {
			#clock-cells = < 0x0 >;              /* in zephyr/dts/arm/st/c0/stm32c0.dtsi:119 */
			compatible = "st,stm32c0-hsi-clock"; /* in zephyr/dts/arm/st/c0/stm32c0.dtsi:120 */
			hsi-div = < 0x1 >;                   /* in zephyr/dts/arm/st/c0/stm32c0.dtsi:121 */
			clock-frequency = < 0x2dc6c00 >;     /* in zephyr/dts/arm/st/c0/stm32c0.dtsi:122 */
			status = "okay";                     /* in zephyr/boards/st/nucleo_c092rc/nucleo_c092rc.dts:104 */
		};

		/* node '/clocks/clk-lse' defined in zephyr/dts/arm/st/c0/stm32c0.dtsi:126 */
		clk_lse: clk-lse {
			#clock-cells = < 0x0 >;            /* in zephyr/dts/arm/st/c0/stm32c0.dtsi:127 */
			compatible = "st,stm32-lse-clock"; /* in zephyr/dts/arm/st/c0/stm32c0.dtsi:128 */
			clock-frequency = < 0x8000 >;      /* in zephyr/dts/arm/st/c0/stm32c0.dtsi:129 */
			driving-capability = < 0x0 >;      /* in zephyr/dts/arm/st/c0/stm32c0.dtsi:130 */
			status = "okay";                   /* in zephyr/boards/st/nucleo_c092rc/nucleo_c092rc.dts:95 */
		};

		/* node '/clocks/clk-lsi' defined in zephyr/dts/arm/st/c0/stm32c0.dtsi:134 */
		clk_lsi: clk-lsi {
			#clock-cells = < 0x0 >;       /* in zephyr/dts/arm/st/c0/stm32c0.dtsi:135 */
			compatible = "fixed-clock";   /* in zephyr/dts/arm/st/c0/stm32c0.dtsi:136 */
			clock-frequency = < 0x7d00 >; /* in zephyr/dts/arm/st/c0/stm32c0.dtsi:137 */
			status = "disabled";          /* in zephyr/dts/arm/st/c0/stm32c0.dtsi:138 */
		};
	};

	/* node '/mcos' defined in zephyr/dts/arm/st/c0/stm32c0.dtsi:142 */
	mcos {

		/* node '/mcos/mco1' defined in zephyr/dts/arm/st/c0/stm32c0.dtsi:143 */
		mco1: mco1 {
			compatible = "st,stm32-clock-mco"; /* in zephyr/dts/arm/st/c0/stm32c0.dtsi:144 */
			status = "disabled";               /* in zephyr/dts/arm/st/c0/stm32c0.dtsi:145 */
		};

		/* node '/mcos/mco2' defined in zephyr/dts/arm/st/c0/stm32c0.dtsi:148 */
		mco2: mco2 {
			compatible = "st,stm32-clock-mco"; /* in zephyr/dts/arm/st/c0/stm32c0.dtsi:149 */
			status = "disabled";               /* in zephyr/dts/arm/st/c0/stm32c0.dtsi:150 */
		};
	};

	/* node '/dietemp' defined in zephyr/dts/arm/st/c0/stm32c0.dtsi:498 */
	die_temp: dietemp {
		compatible = "st,stm32c0-temp-cal"; /* in zephyr/dts/arm/st/c0/stm32c0.dtsi:499 */
		ts-cal1-addr = < 0x1fff7568 >;      /* in zephyr/dts/arm/st/c0/stm32c0.dtsi:500 */
		ts-cal1-temp = < 0x1e >;            /* in zephyr/dts/arm/st/c0/stm32c0.dtsi:501 */
		ts-cal-vrefanalog = < 0xbb8 >;      /* in zephyr/dts/arm/st/c0/stm32c0.dtsi:502 */
		avgslope = "2.53";                  /* in zephyr/dts/arm/st/c0/stm32c0.dtsi:503 */
		io-channels = < &adc1 0x9 >;        /* in zephyr/dts/arm/st/c0/stm32c0.dtsi:504 */
		status = "okay";                    /* in zephyr/boards/st/nucleo_c092rc/nucleo_c092rc.dts:176 */
	};

	/* node '/vref' defined in zephyr/dts/arm/st/c0/stm32c0.dtsi:508 */
	vref: vref {
		compatible = "st,stm32-vref";      /* in zephyr/dts/arm/st/c0/stm32c0.dtsi:509 */
		vrefint-cal-addr = < 0x1fff756a >; /* in zephyr/dts/arm/st/c0/stm32c0.dtsi:510 */
		vrefint-cal-mv = < 0xbb8 >;        /* in zephyr/dts/arm/st/c0/stm32c0.dtsi:511 */
		io-channels = < &adc1 0xa >;       /* in zephyr/dts/arm/st/c0/stm32c0.dtsi:512 */
		status = "okay";                   /* in zephyr/boards/st/nucleo_c092rc/nucleo_c092rc.dts:180 */
	};

	/* node '/smbus1' defined in zephyr/dts/arm/st/c0/stm32c0.dtsi:516 */
	smbus1: smbus1 {
		compatible = "st,stm32-smbus"; /* in zephyr/dts/arm/st/c0/stm32c0.dtsi:517 */
		#address-cells = < 0x1 >;      /* in zephyr/dts/arm/st/c0/stm32c0.dtsi:518 */
		#size-cells = < 0x0 >;         /* in zephyr/dts/arm/st/c0/stm32c0.dtsi:519 */
		i2c = < &i2c1 >;               /* in zephyr/dts/arm/st/c0/stm32c0.dtsi:520 */
		status = "disabled";           /* in zephyr/dts/arm/st/c0/stm32c0.dtsi:521 */
	};

	/* node '/connector' defined in zephyr/boards/st/nucleo_c092rc/arduino_r3_connector.dtsi:11 */
	arduino_header: connector {
		compatible = "arduino-header-r3";          /* in zephyr/boards/st/nucleo_c092rc/arduino_r3_connector.dtsi:12 */
		#gpio-cells = < 0x2 >;                     /* in zephyr/boards/st/nucleo_c092rc/arduino_r3_connector.dtsi:13 */
		gpio-map-mask = < 0xffffffff 0xffffffc0 >; /* in zephyr/boards/st/nucleo_c092rc/arduino_r3_connector.dtsi:14 */
		gpio-map-pass-thru = < 0x0 0x3f >;         /* in zephyr/boards/st/nucleo_c092rc/arduino_r3_connector.dtsi:15 */
		gpio-map = < 0x0 0x0 &gpioa 0x0 0x0 >,
		           < 0x1 0x0 &gpioa 0x1 0x0 >,
		           < 0x2 0x0 &gpioa 0x4 0x0 >,
		           < 0x3 0x0 &gpiob 0x0 0x0 >,
		           < 0x4 0x0 &gpioc 0x4 0x0 >,
		           < 0x5 0x0 &gpioc 0x5 0x0 >,
		           < 0x6 0x0 &gpiob 0x7 0x0 >,
		           < 0x7 0x0 &gpiob 0x6 0x0 >,
		           < 0x8 0x0 &gpioa 0xa 0x0 >,
		           < 0x9 0x0 &gpioc 0x7 0x0 >,
		           < 0xa 0x0 &gpiob 0x5 0x0 >,
		           < 0xb 0x0 &gpiob 0x4 0x0 >,
		           < 0xc 0x0 &gpioc 0x8 0x0 >,
		           < 0xd 0x0 &gpioa 0x8 0x0 >,
		           < 0xe 0x0 &gpioa 0x9 0x0 >,
		           < 0xf 0x0 &gpiob 0x3 0x0 >,
		           < 0x10 0x0 &gpioa 0xf 0x0 >,
		           < 0x11 0x0 &gpioa 0x7 0x0 >,
		           < 0x12 0x0 &gpioa 0x6 0x0 >,
		           < 0x13 0x0 &gpioa 0x5 0x0 >,
		           < 0x14 0x0 &gpiob 0x9 0x0 >,
		           < 0x15 0x0 &gpiob 0x8 0x0 >;    /* in zephyr/boards/st/nucleo_c092rc/arduino_r3_connector.dtsi:16 */
	};

	/* node '/leds' defined in zephyr/boards/st/nucleo_c092rc/nucleo_c092rc.dts:26 */
	leds: leds {
		compatible = "gpio-leds"; /* in zephyr/boards/st/nucleo_c092rc/nucleo_c092rc.dts:27 */

		/* node '/leds/led_1' defined in zephyr/boards/st/nucleo_c092rc/nucleo_c092rc.dts:29 */
		green_led_1: led_1 {
			gpios = < &gpioa 0x5 0x0 >; /* in zephyr/boards/st/nucleo_c092rc/nucleo_c092rc.dts:30 */
			label = "User LD1";         /* in zephyr/boards/st/nucleo_c092rc/nucleo_c092rc.dts:31 */
		};

		/* node '/leds/led_2' defined in zephyr/boards/st/nucleo_c092rc/nucleo_c092rc.dts:34 */
		blue_led: led_2 {
			gpios = < &gpioc 0x9 0x1 >; /* in zephyr/boards/st/nucleo_c092rc/nucleo_c092rc.dts:35 */
			label = "User LD2";         /* in zephyr/boards/st/nucleo_c092rc/nucleo_c092rc.dts:36 */
		};
	};

	/* node '/pwmleds' defined in zephyr/boards/st/nucleo_c092rc/nucleo_c092rc.dts:40 */
	pwmleds {
		compatible = "pwm-leds"; /* in zephyr/boards/st/nucleo_c092rc/nucleo_c092rc.dts:41 */

		/* node '/pwmleds/green_pwm_led' defined in zephyr/boards/st/nucleo_c092rc/nucleo_c092rc.dts:43 */
		green_pwm_led: green_pwm_led {
			pwms = < &pwm1 0x1 0x1312d00 0x0 >; /* in zephyr/boards/st/nucleo_c092rc/nucleo_c092rc.dts:44 */
		};
	};

	/* node '/gpio_keys' defined in zephyr/boards/st/nucleo_c092rc/nucleo_c092rc.dts:48 */
	gpio_keys {
		compatible = "gpio-keys"; /* in zephyr/boards/st/nucleo_c092rc/nucleo_c092rc.dts:49 */

		/* node '/gpio_keys/button' defined in zephyr/boards/st/nucleo_c092rc/nucleo_c092rc.dts:51 */
		user_button: button {
			label = "user button";       /* in zephyr/boards/st/nucleo_c092rc/nucleo_c092rc.dts:52 */
			gpios = < &gpioc 0xd 0x11 >; /* in zephyr/boards/st/nucleo_c092rc/nucleo_c092rc.dts:53 */
			status = "okay";             /* in zephyr/boards/st/nucleo_c092rc/nucleo_c092rc.dts:54 */
			zephyr,code = < 0xb >;       /* in zephyr/boards/st/nucleo_c092rc/nucleo_c092rc.dts:55 */
		};
	};

	/* node '/can-phy0' defined in zephyr/boards/st/nucleo_c092rc/nucleo_c092rc.dts:59 */
	transceiver0: can-phy0 {
		compatible = "microchip,mcp2562fd",
		             "can-transceiver-gpio"; /* in zephyr/boards/st/nucleo_c092rc/nucleo_c092rc.dts:60 */
		standby-gpios = < &gpiod 0x2 0x0 >;  /* in zephyr/boards/st/nucleo_c092rc/nucleo_c092rc.dts:61 */
		max-bitrate = < 0x4c4b40 >;          /* in zephyr/boards/st/nucleo_c092rc/nucleo_c092rc.dts:62 */
		#phy-cells = < 0x0 >;                /* in zephyr/boards/st/nucleo_c092rc/nucleo_c092rc.dts:63 */
		phandle = < 0x18 >;                  /* in zephyr/boards/st/nucleo_c092rc/nucleo_c092rc.dts:199 */
	};
};
